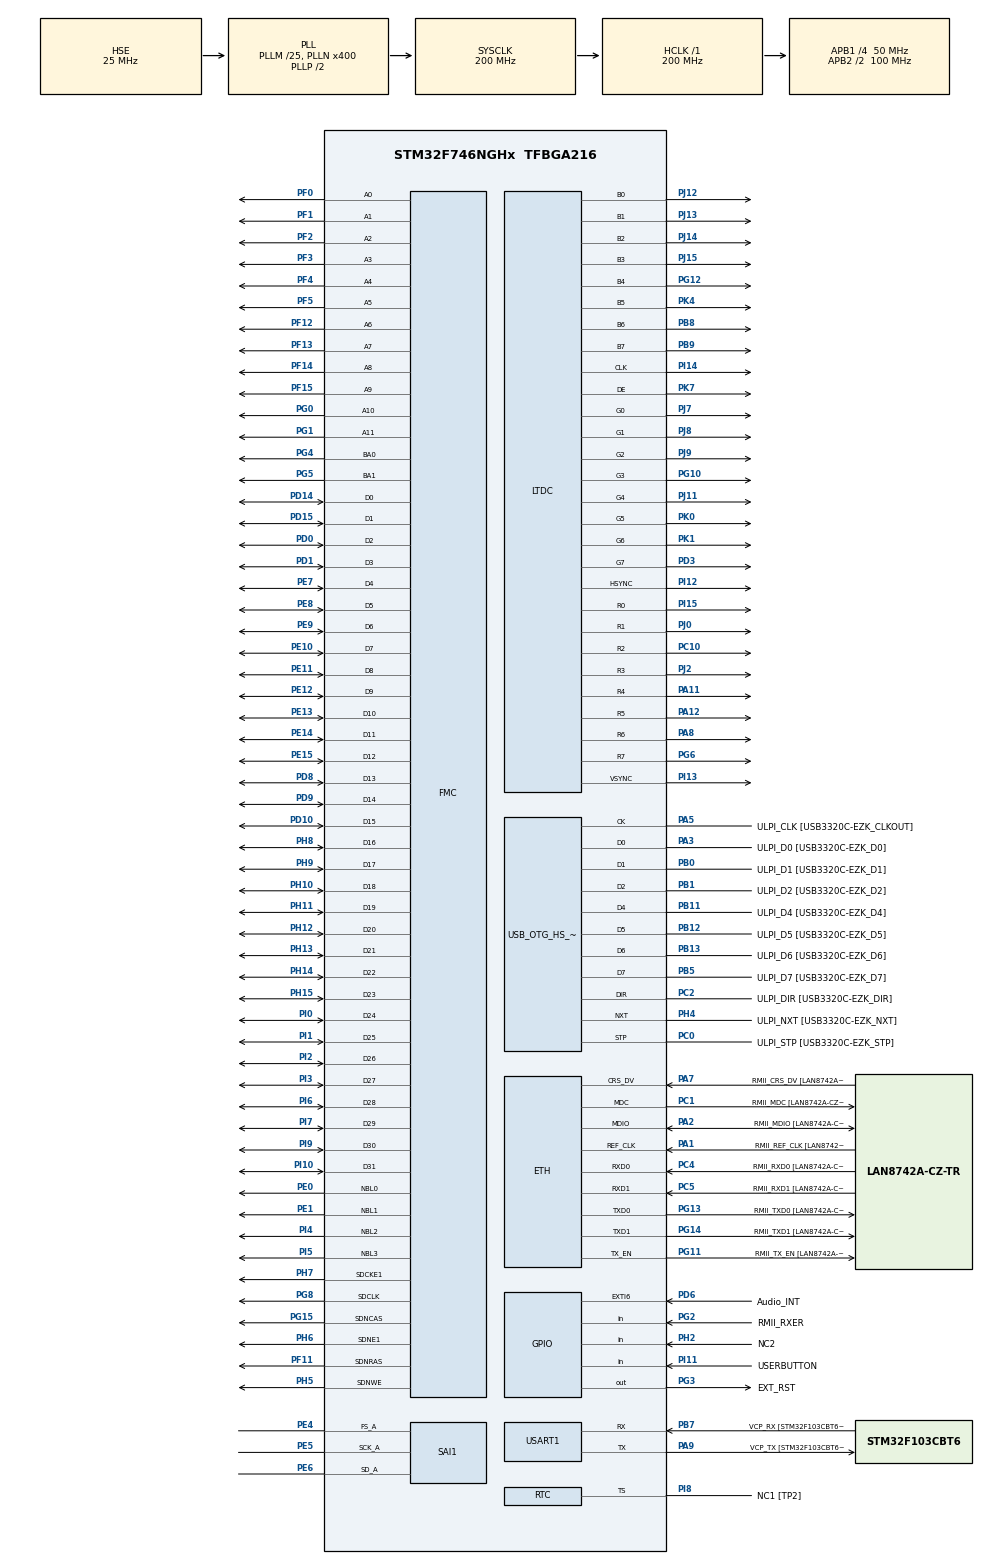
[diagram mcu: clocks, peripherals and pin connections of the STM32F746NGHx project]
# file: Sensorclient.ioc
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CORTEX_M7.CPU_DCache=Enabled
CORTEX_M7.CPU_ICache=Enabled
CORTEX_M7.PREFETCH_ENABLE=1
CORTEX_M7.default_mode_Activation=0
ETH.MACAddr=00\:80\:E1\:00\:00\:01
ETH.MediaInterface=HAL_ETH_RMII_MODE
ETH.PHY_Name=LAN8742A_PHY_ADDRESS
ETH.PHY_RESET_DELAY=0x00000FFF
ETH.PhyAddress=0
FMC.CASLatency1=FMC_SDRAM_CAS_LATENCY_3
FMC.ExitSelfRefreshDelay1=6
FMC.LoadToActiveDelay1=2
FMC.RCDDelay1=2
FMC.RPDelay1=2
FMC.RPDelay2=2
FMC.RowCycleDelay1=6
FMC.RowCycleDelay2=6
FMC.SDClockPeriod1=FMC_SDRAM_CLOCK_PERIOD_2
FMC.SDClockPeriod2=FMC_SDRAM_CLOCK_PERIOD_2
FMC.SelfRefreshTime1=4
FMC.WriteRecoveryTime1=2
LWIP.BSP.number=1
LWIP.LWIP_DBG_TYPES_ON=LWIP_DBG_ON
LWIP.LWIP_TCP=1
LWIP.MEMP_NUM_TCP_PCB=1
LWIP.MEMP_NUM_UDP_PCB=1
LWIP.Version=v2.1.2_Cube
LWIP0.BSP.STBoard=false
LWIP0.BSP.api=BSP_COMPONENT_DRIVER
LWIP0.BSP.component=LAN8742
LWIP0.BSP.instance=LAN8742
LWIP0.BSP.name=Driver_PHY
LWIP0.BSP.semaphore=S_LAN8742
LWIP0.BSP.solution=LAN8742
Mcu.Family=STM32F7
Mcu.Name=STM32F746NGHx
Mcu.Package=TFBGA216
NVIC.DMA2D_IRQn=true\:0\:0\:false\:false\:true\:true\:true\:true
NVIC.LTDC_ER_IRQn=true\:0\:0\:false\:false\:true\:true\:true\:true
NVIC.LTDC_IRQn=true\:0\:0\:false\:false\:true\:true\:true\:true
NVIC.PriorityGroup=NVIC_PRIORITYGROUP_4
NVIC.SAI1_IRQn=true\:0\:0\:false\:false\:true\:true\:true\:true
NVIC.TIM6_DAC_IRQn=true\:15\:0\:false\:false\:true\:false\:true\:true
NVIC.TimeBase=TIM6_DAC_IRQn
NVIC.TimeBaseIP=TIM6
PA1.GPIO_Label=RMII_REF_CLK [LAN8742A-CZ-TR_REFCLK0]
PA1.Mode=RMII
PA1.Signal=ETH_REF_CLK
PA11.Mode=RGB888
PA11.Signal=LTDC_R4
PA12.Mode=RGB888
PA12.Signal=LTDC_R5
PA13.GPIO_Label=SWDIO
PA13.Mode=Serial_Wire
PA13.Signal=SYS_JTMS-SWDIO
PA14.GPIO_Label=SWCLK
PA14.Mode=Serial_Wire
PA14.Signal=SYS_JTCK-SWCLK
PA2.GPIO_Label=RMII_MDIO [LAN8742A-CZ-TR_MDIO]
PA2.Mode=RMII
PA2.Signal=ETH_MDIO
PA3.GPIO_Label=ULPI_D0 [USB3320C-EZK_D0]
PA3.Mode=Host_HS
PA3.Signal=USB_OTG_HS_ULPI_D0
PA5.GPIO_Label=ULPI_CLK [USB3320C-EZK_CLKOUT]
PA5.Mode=Host_HS
PA5.Signal=USB_OTG_HS_ULPI_CK
PA7.GPIO_Label=RMII_CRS_DV [LAN8742A-CZ-TR_CRS_DV]
PA7.Mode=RMII
PA7.Signal=ETH_CRS_DV
PA8.Mode=RGB888
PA8.Signal=LTDC_R6
PA9.GPIO_Label=VCP_TX [STM32F103CBT6_PA3]
PA9.GPIO_Mode=GPIO_MODE_AF_PP
PA9.GPIO_PuPd=GPIO_NOPULL
PA9.GPIO_Speed=GPIO_SPEED_FREQ_LOW
PA9.Mode=Asynchronous
PA9.Signal=USART1_TX
PB0.GPIO_Label=ULPI_D1 [USB3320C-EZK_D1]
PB0.Mode=Host_HS
PB0.Signal=USB_OTG_HS_ULPI_D1
PB1.GPIO_Label=ULPI_D2 [USB3320C-EZK_D2]
PB1.Mode=Host_HS
PB1.Signal=USB_OTG_HS_ULPI_D2
PB11.GPIO_Label=ULPI_D4 [USB3320C-EZK_D4]
PB11.Mode=Host_HS
PB11.Signal=USB_OTG_HS_ULPI_D4
PB12.GPIO_Label=ULPI_D5 [USB3320C-EZK_D5]
PB12.Mode=Host_HS
PB12.Signal=USB_OTG_HS_ULPI_D5
PB13.GPIO_Label=ULPI_D6 [USB3320C-EZK_D6]
PB13.Mode=Host_HS
PB13.Signal=USB_OTG_HS_ULPI_D6
PB2.Signal=QUADSPI_CLK
PB5.GPIO_Label=ULPI_D7 [USB3320C-EZK_D7]
PB5.Mode=Host_HS
PB5.Signal=USB_OTG_HS_ULPI_D7
PB6.GPIO_Label=QSPI_NCS [N25Q128A13EF840E_S]
PB6.Signal=QUADSPI_BK1_NCS
PB7.GPIO_Label=VCP_RX [STM32F103CBT6_PA2]
PB7.GPIO_Mode=GPIO_MODE_AF_PP
PB7.GPIO_PuPd=GPIO_NOPULL
PB7.GPIO_Speed=GPIO_SPEED_FREQ_LOW
PB7.Mode=Asynchronous
PB7.Signal=USART1_RX
PB8.Mode=RGB888
PB8.Signal=LTDC_B6
PB9.Mode=RGB888
PB9.Signal=LTDC_B7
PC0.GPIO_Label=ULPI_STP [USB3320C-EZK_STP]
PC0.Mode=Host_HS
PC0.Signal=USB_OTG_HS_ULPI_STP
PC1.GPIO_Label=RMII_MDC [LAN8742A-CZ-TR_MDC]
PC1.Mode=RMII
PC1.Signal=ETH_MDC
PC10.Mode=RGB888
PC10.Signal=LTDC_R2
PC14/OSC32_IN.GPIO_Label=RCC_OSC32_IN
PC14/OSC32_IN.Mode=LSE-External-Oscillator
PC14/OSC32_IN.Signal=RCC_OSC32_IN
PC15/OSC32_OUT.GPIO_Label=RCC_OSC32_OUT
PC15/OSC32_OUT.Mode=LSE-External-Oscillator
PC15/OSC32_OUT.Signal=RCC_OSC32_OUT
PC2.GPIO_Label=ULPI_DIR [USB3320C-EZK_DIR]
PC2.Mode=Host_HS
PC2.Signal=USB_OTG_HS_ULPI_DIR
PC3.GPIO_Label=FMC_SDCKE0 [MT48LC4M32B2B5-6A_CKE]
PC3.Signal=FMC_SDCKE0
PC4.GPIO_Label=RMII_RXD0 [LAN8742A-CZ-TR_RXD0]
PC4.Mode=RMII
PC4.Signal=ETH_RXD0
PC5.GPIO_Label=RMII_RXD1 [LAN8742A-CZ-TR_RXD1]
PC5.Mode=RMII
PC5.Signal=ETH_RXD1
PD0.Signal=FMC_D2_DA2
PD1.Signal=FMC_D3_DA3
PD10.GPIO_Mode=GPIO_MODE_AF_PP
PD10.GPIO_PuPd=GPIO_NOPULL
PD10.GPIO_Speed_High_Default=GPIO_SPEED_FREQ_VERY_HIGH
PD10.Signal=FMC_D15_DA15
PD11.GPIO_Label=QSPI_D0 [N25Q128A13EF840E_DQ0]
PD11.Signal=QUADSPI_BK1_IO0
PD12.GPIO_Label=QSPI_D1 [N25Q128A13EF840E_DQ1]
PD12.Signal=QUADSPI_BK1_IO1
PD13.GPIO_Label=QSPI_D3 [N25Q128A13EF840E_DQ3]
PD13.Signal=QUADSPI_BK1_IO3
PD14.GPIO_Mode=GPIO_MODE_AF_PP
PD14.GPIO_PuPd=GPIO_NOPULL
PD14.GPIO_Speed_High_Default=GPIO_SPEED_FREQ_VERY_HIGH
PD14.Signal=FMC_D0_DA0
PD15.GPIO_Mode=GPIO_MODE_AF_PP
PD15.GPIO_PuPd=GPIO_NOPULL
PD15.GPIO_Speed_High_Default=GPIO_SPEED_FREQ_VERY_HIGH
PD15.Signal=FMC_D1_DA1
PD3.Mode=RGB888
PD3.Signal=LTDC_G7
PD6.GPIO_Label=Audio_INT
PD6.GPIO_ModeDefaultEXTI=GPIO_MODE_EVT_RISING
PD6.Signal=GPXTI6
PD8.GPIO_Mode=GPIO_MODE_AF_PP
PD8.GPIO_PuPd=GPIO_NOPULL
PD8.GPIO_Speed_High_Default=GPIO_SPEED_FREQ_VERY_HIGH
PD8.Signal=FMC_D13_DA13
PD9.GPIO_Mode=GPIO_MODE_AF_PP
PD9.GPIO_PuPd=GPIO_NOPULL
PD9.GPIO_Speed_High_Default=GPIO_SPEED_FREQ_VERY_HIGH
PD9.Signal=FMC_D14_DA14
PE0.GPIO_Mode=GPIO_MODE_AF_PP
PE0.GPIO_PuPd=GPIO_NOPULL
PE0.GPIO_Speed_High_Default=GPIO_SPEED_FREQ_VERY_HIGH
PE0.Signal=FMC_NBL0
PE1.GPIO_Mode=GPIO_MODE_AF_PP
PE1.GPIO_PuPd=GPIO_NOPULL
PE1.GPIO_Speed_High_Default=GPIO_SPEED_FREQ_VERY_HIGH
PE1.Signal=FMC_NBL1
PE10.GPIO_Mode=GPIO_MODE_AF_PP
PE10.GPIO_PuPd=GPIO_NOPULL
PE10.GPIO_Speed_High_Default=GPIO_SPEED_FREQ_VERY_HIGH
PE10.Signal=FMC_D7_DA7
PE11.GPIO_Mode=GPIO_MODE_AF_PP
PE11.GPIO_PuPd=GPIO_NOPULL
PE11.GPIO_Speed_High_Default=GPIO_SPEED_FREQ_VERY_HIGH
PE11.Signal=FMC_D8_DA8
PE12.GPIO_Mode=GPIO_MODE_AF_PP
PE12.GPIO_PuPd=GPIO_NOPULL
PE12.GPIO_Speed_High_Default=GPIO_SPEED_FREQ_VERY_HIGH
PE12.Signal=FMC_D9_DA9
PE13.GPIO_Mode=GPIO_MODE_AF_PP
PE13.GPIO_PuPd=GPIO_NOPULL
PE13.GPIO_Speed_High_Default=GPIO_SPEED_FREQ_VERY_HIGH
PE13.Signal=FMC_D10_DA10
PE14.GPIO_Mode=GPIO_MODE_AF_PP
PE14.GPIO_PuPd=GPIO_NOPULL
PE14.GPIO_Speed_High_Default=GPIO_SPEED_FREQ_VERY_HIGH
PE14.Signal=FMC_D11_DA11
PE15.GPIO_Mode=GPIO_MODE_AF_PP
PE15.GPIO_PuPd=GPIO_NOPULL
PE15.GPIO_Speed_High_Default=GPIO_SPEED_FREQ_VERY_HIGH
PE15.Signal=FMC_D12_DA12
PE2.GPIO_Label=QSPI_D2 [N25Q128A13EF840E_DQ2]
PE2.Signal=QUADSPI_BK1_IO2
PE4.Mode=SAI_A_Master
PE4.Signal=SAI1_FS_A
PE5.Mode=SAI_A_Master
PE5.Signal=SAI1_SCK_A
PE6.Mode=SAI_A_Master
PE6.Signal=SAI1_SD_A
PE7.GPIO_Mode=GPIO_MODE_AF_PP
PE7.GPIO_PuPd=GPIO_NOPULL
PE7.GPIO_Speed_High_Default=GPIO_SPEED_FREQ_VERY_HIGH
PE7.Signal=FMC_D4_DA4
PE8.GPIO_Mode=GPIO_MODE_AF_PP
PE8.GPIO_PuPd=GPIO_NOPULL
PE8.GPIO_Speed_High_Default=GPIO_SPEED_FREQ_VERY_HIGH
PE8.Signal=FMC_D5_DA5
PE9.GPIO_Mode=GPIO_MODE_AF_PP
PE9.GPIO_PuPd=GPIO_NOPULL
PE9.GPIO_Speed_High_Default=GPIO_SPEED_FREQ_VERY_HIGH
PE9.Signal=FMC_D6_DA6
PF0.GPIO_Mode=GPIO_MODE_AF_PP
PF0.GPIO_PuPd=GPIO_NOPULL
PF0.GPIO_Speed_High_Default=GPIO_SPEED_FREQ_VERY_HIGH
PF0.Signal=FMC_A0
PF1.GPIO_Mode=GPIO_MODE_AF_PP
PF1.GPIO_PuPd=GPIO_NOPULL
PF1.GPIO_Speed_High_Default=GPIO_SPEED_FREQ_VERY_HIGH
PF1.Signal=FMC_A1
PF11.GPIO_Mode=GPIO_MODE_AF_PP
PF11.GPIO_PuPd=GPIO_NOPULL
PF11.GPIO_Speed_High_Default=GPIO_SPEED_FREQ_VERY_HIGH
PF11.Signal=FMC_SDNRAS
PF12.GPIO_Mode=GPIO_MODE_AF_PP
PF12.GPIO_PuPd=GPIO_NOPULL
PF12.GPIO_Speed_High_Default=GPIO_SPEED_FREQ_VERY_HIGH
PF12.Signal=FMC_A6
PF13.GPIO_Mode=GPIO_MODE_AF_PP
PF13.GPIO_PuPd=GPIO_NOPULL
PF13.GPIO_Speed_High_Default=GPIO_SPEED_FREQ_VERY_HIGH
PF13.Signal=FMC_A7
PF14.GPIO_Mode=GPIO_MODE_AF_PP
PF14.GPIO_PuPd=GPIO_NOPULL
PF14.GPIO_Speed_High_Default=GPIO_SPEED_FREQ_VERY_HIGH
PF14.Signal=FMC_A8
PF15.GPIO_Mode=GPIO_MODE_AF_PP
PF15.GPIO_PuPd=GPIO_NOPULL
PF15.GPIO_Speed_High_Default=GPIO_SPEED_FREQ_VERY_HIGH
PF15.Signal=FMC_A9
PF2.GPIO_Mode=GPIO_MODE_AF_PP
PF2.GPIO_PuPd=GPIO_NOPULL
PF2.GPIO_Speed_High_Default=GPIO_SPEED_FREQ_VERY_HIGH
PF2.Signal=FMC_A2
PF3.GPIO_Mode=GPIO_MODE_AF_PP
PF3.GPIO_PuPd=GPIO_NOPULL
PF3.GPIO_Speed_High_Default=GPIO_SPEED_FREQ_VERY_HIGH
PF3.Signal=FMC_A3
PF4.GPIO_Mode=GPIO_MODE_AF_PP
PF4.GPIO_PuPd=GPIO_NOPULL
PF4.GPIO_Speed_High_Default=GPIO_SPEED_FREQ_VERY_HIGH
PF4.Signal=FMC_A4
PF5.GPIO_Mode=GPIO_MODE_AF_PP
PF5.GPIO_PuPd=GPIO_NOPULL
PF5.GPIO_Speed_High_Default=GPIO_SPEED_FREQ_VERY_HIGH
PF5.Signal=FMC_A5
PG0.GPIO_Mode=GPIO_MODE_AF_PP
PG0.GPIO_PuPd=GPIO_NOPULL
PG0.GPIO_Speed_High_Default=GPIO_SPEED_FREQ_VERY_HIGH
PG0.Signal=FMC_A10
PG1.GPIO_Mode=GPIO_MODE_AF_PP
PG1.GPIO_PuPd=GPIO_NOPULL
PG1.GPIO_Speed_High_Default=GPIO_SPEED_FREQ_VERY_HIGH
PG1.Signal=FMC_A11
PG10.Mode=RGB888
PG10.Signal=LTDC_G3
PG11.GPIO_Label=RMII_TX_EN [LAN8742A-CZ-TR_TXEN]
PG11.Mode=RMII
PG11.Signal=ETH_TX_EN
PG12.Mode=RGB888
PG12.Signal=LTDC_B4
PG13.GPIO_Label=RMII_TXD0 [LAN8742A-CZ-TR_TXD0]
PG13.Mode=RMII
PG13.Signal=ETH_TXD0
PG14.GPIO_Label=RMII_TXD1 [LAN8742A-CZ-TR_TXD1]
PG14.Mode=RMII
PG14.Signal=ETH_TXD1
PG15.GPIO_Mode=GPIO_MODE_AF_PP
PG15.GPIO_PuPd=GPIO_NOPULL
PG15.GPIO_Speed_High_Default=GPIO_SPEED_FREQ_VERY_HIGH
PG15.Signal=FMC_SDNCAS
PG2.GPIO_Label=RMII_RXER
PG2.Signal=GPIO_Input
PG3.GPIO_Label=EXT_RST
PG3.Signal=GPIO_Output
PG4.GPIO_Mode=GPIO_MODE_AF_PP
PG4.GPIO_PuPd=GPIO_NOPULL
PG4.GPIO_Speed_High_Default=GPIO_SPEED_FREQ_VERY_HIGH
PG4.Signal=FMC_A14_BA0
PG5.GPIO_Mode=GPIO_MODE_AF_PP
PG5.GPIO_PuPd=GPIO_NOPULL
PG5.GPIO_Speed_High_Default=GPIO_SPEED_FREQ_VERY_HIGH
PG5.Signal=FMC_A15_BA1
PG6.Mode=RGB888
PG6.Signal=LTDC_R7
PG8.GPIO_Mode=GPIO_MODE_AF_PP
PG8.GPIO_PuPd=GPIO_NOPULL
PG8.GPIO_Speed_High_Default=GPIO_SPEED_FREQ_VERY_HIGH
PG8.Signal=FMC_SDCLK
PH0/OSC_IN.GPIO_Label=OSC_25M [NZ2520SB-25.00M_OUT]
PH0/OSC_IN.Mode=HSE-External-Oscillator
PH0/OSC_IN.Signal=RCC_OSC_IN
PH1/OSC_OUT.Mode=HSE-External-Oscillator
PH1/OSC_OUT.Signal=RCC_OSC_OUT
PH10.Signal=FMC_D18
PH11.Signal=FMC_D19
PH12.Signal=FMC_D20
PH13.Signal=FMC_D21
PH14.Signal=FMC_D22
PH15.Signal=FMC_D23
PH2.GPIO_Label=NC2
PH2.Signal=GPIO_Input
PH3.GPIO_Label=FMC_SDNE0 [MT48LC4M32B2B5-6A_CS]
PH3.Signal=FMC_SDNE0
PH4.GPIO_Label=ULPI_NXT [USB3320C-EZK_NXT]
PH4.Mode=Host_HS
PH4.Signal=USB_OTG_HS_ULPI_NXT
PH5.GPIO_Mode=GPIO_MODE_AF_PP
PH5.GPIO_PuPd=GPIO_NOPULL
PH5.GPIO_Speed_High_Default=GPIO_SPEED_FREQ_VERY_HIGH
PH5.Signal=FMC_SDNWE
PH6.Mode=SdramChipSelect2_1
PH6.Signal=FMC_SDNE1
PH7.Mode=SdramChipSelect2_1
PH7.Signal=FMC_SDCKE1
PH8.Signal=FMC_D16
PH9.Signal=FMC_D17
PI0.Signal=FMC_D24
PI1.Signal=FMC_D25
PI10.Signal=FMC_D31
PI11.GPIO_Label=USERBUTTON
PI11.GPIO_PuPd=GPIO_NOPULL
PI11.Signal=GPIO_Input
PI12.Mode=RGB888
PI12.Signal=LTDC_HSYNC
PI13.Mode=RGB888
PI13.Signal=LTDC_VSYNC
PI14.Mode=RGB888
PI14.Signal=LTDC_CLK
PI15.Mode=RGB888
PI15.Signal=LTDC_R0
PI2.Signal=FMC_D26
PI3.Signal=FMC_D27
PI4.Signal=FMC_NBL2
PI5.Signal=FMC_NBL3
PI6.Signal=FMC_D28
PI7.Signal=FMC_D29
PI8.GPIO_Label=NC1 [TP2]
PI8.Mode=Timestamp enabled - Input Enabled to TS
PI8.Signal=RTC_TS
PI9.Signal=FMC_D30
PJ0.Mode=RGB888
PJ0.Signal=LTDC_R1
PJ11.Mode=RGB888
PJ11.Signal=LTDC_G4
PJ12.Mode=RGB888
PJ12.Signal=LTDC_B0
PJ13.Mode=RGB888
PJ13.Signal=LTDC_B1
PJ14.Mode=RGB888
PJ14.Signal=LTDC_B2
PJ15.Mode=RGB888
PJ15.Signal=LTDC_B3
PJ2.Mode=RGB888
PJ2.Signal=LTDC_R3
PJ7.Mode=RGB888
PJ7.Signal=LTDC_G0
PJ8.Mode=RGB888
PJ8.Signal=LTDC_G1
PJ9.Mode=RGB888
PJ9.Signal=LTDC_G2
PK0.Mode=RGB888
PK0.Signal=LTDC_G5
PK1.Mode=RGB888
PK1.Signal=LTDC_G6
PK4.Mode=RGB888
PK4.Signal=LTDC_B5
PK7.Mode=RGB888
PK7.Signal=LTDC_DE
ProjectManager.HeapSize=0x200
ProjectManager.StackSize=0x400
ProjectManager.TargetToolchain=STM32CubeIDE
RCC.AHBFreq_Value=200000000
RCC.APB1CLKDivider=RCC_HCLK_DIV4
RCC.APB1Freq_Value=50000000
RCC.APB1TimFreq_Value=100000000
RCC.APB2CLKDivider=RCC_HCLK_DIV2
RCC.APB2Freq_Value=100000000
RCC.APB2TimFreq_Value=200000000
RCC.CortexFreq_Value=200000000
RCC.HCLKFreq_Value=200000000
RCC.HSE_VALUE=25000000
RCC.HSI_VALUE=16000000
RCC.PLL48CLockSelection=RCC_CLK48SOURCE_PLLSAIP
RCC.PLLI2SN=100
RCC.PLLM=25
RCC.PLLN=400
RCC.PLLQ=9
RCC.PLLSAIN=384
RCC.PLLSAIP=RCC_PLLSAIP_DIV8
RCC.PLLSAIR=5
RCC.PLLSAIRDiv=RCC_PLLSAIDIVR_8
RCC.PLLSourceVirtual=RCC_PLLSOURCE_HSE
RCC.SDMMCClockSelection=RCC_SDMMC1CLKSOURCE_CLK48
RCC.SYSCLKFreq_VALUE=200000000
RCC.SYSCLKSource=RCC_SYSCLKSOURCE_PLLCLK
RCC.USBFreq_Value=48000000
RCC.VCOOutputFreq_Value=400000000
SAI1.AudioFrequency-SAI_A_Master=SAI_AUDIO_FREQUENCY_192K
SAI1.AudioMode-SAI_A_Master=SAI_MODEMASTER_RX
SAI1.BasicDataSize-SAI_A_Master=SAI_PROTOCOL_DATASIZE_32BIT
SAI1.BasicProtocol-SAI_A_Master=SAI_PCM_LONG
SAI1.ErrorAudioFreq-SAI_A_Master=-2.34 %
SAI1.InitProtocol-SAI_A_Master=Enable
SAI1.Instance-SAI_A_Master=SAI$Index_Block_A
SAI1.MClockEnable-SAI_A_Master=SAI_MASTERCLOCK_DISABLE
SAI1.OutputDrive-SAI_A_Master=SAI_OUTPUTDRIVE_ENABLE
SAI1.RealAudioFreq-SAI_A_Master=187.5 KHz
SAI1.VirtualMode-SAI_A_Master=VM_MASTER
SAI1.VirtualProtocol-SAI_A_BASIC=VM_BASIC_PROTOCOL
SH.FMC_A0.0=FMC_A0,12b-sda1
SH.FMC_A1.0=FMC_A1,12b-sda1
SH.FMC_A10.0=FMC_A10,12b-sda1
SH.FMC_A11.0=FMC_A11,12b-sda1
SH.FMC_A14_BA0.0=FMC_BA0,FourSdramBanks1
SH.FMC_A15_BA1.0=FMC_BA1,FourSdramBanks1
SH.FMC_A2.0=FMC_A2,12b-sda1
SH.FMC_A3.0=FMC_A3,12b-sda1
SH.FMC_A4.0=FMC_A4,12b-sda1
SH.FMC_A5.0=FMC_A5,12b-sda1
SH.FMC_A6.0=FMC_A6,12b-sda1
SH.FMC_A7.0=FMC_A7,12b-sda1
SH.FMC_A8.0=FMC_A8,12b-sda1
SH.FMC_A9.0=FMC_A9,12b-sda1
SH.FMC_D0_DA0.0=FMC_D0,sd-32b-d1
SH.FMC_D10_DA10.0=FMC_D10,sd-32b-d1
SH.FMC_D11_DA11.0=FMC_D11,sd-32b-d1
SH.FMC_D12_DA12.0=FMC_D12,sd-32b-d1
SH.FMC_D13_DA13.0=FMC_D13,sd-32b-d1
SH.FMC_D14_DA14.0=FMC_D14,sd-32b-d1
SH.FMC_D15_DA15.0=FMC_D15,sd-32b-d1
SH.FMC_D16.0=FMC_D16,sd-32b-d1
SH.FMC_D17.0=FMC_D17,sd-32b-d1
SH.FMC_D18.0=FMC_D18,sd-32b-d1
SH.FMC_D19.0=FMC_D19,sd-32b-d1
SH.FMC_D1_DA1.0=FMC_D1,sd-32b-d1
SH.FMC_D20.0=FMC_D20,sd-32b-d1
SH.FMC_D21.0=FMC_D21,sd-32b-d1
SH.FMC_D22.0=FMC_D22,sd-32b-d1
SH.FMC_D23.0=FMC_D23,sd-32b-d1
SH.FMC_D24.0=FMC_D24,sd-32b-d1
SH.FMC_D25.0=FMC_D25,sd-32b-d1
SH.FMC_D26.0=FMC_D26,sd-32b-d1
SH.FMC_D27.0=FMC_D27,sd-32b-d1
SH.FMC_D28.0=FMC_D28,sd-32b-d1
SH.FMC_D29.0=FMC_D29,sd-32b-d1
SH.FMC_D2_DA2.0=FMC_D2,sd-32b-d1
SH.FMC_D30.0=FMC_D30,sd-32b-d1
SH.FMC_D31.0=FMC_D31,sd-32b-d1
SH.FMC_D3_DA3.0=FMC_D3,sd-32b-d1
SH.FMC_D4_DA4.0=FMC_D4,sd-32b-d1
SH.FMC_D5_DA5.0=FMC_D5,sd-32b-d1
SH.FMC_D6_DA6.0=FMC_D6,sd-32b-d1
SH.FMC_D7_DA7.0=FMC_D7,sd-32b-d1
SH.FMC_D8_DA8.0=FMC_D8,sd-32b-d1
SH.FMC_D9_DA9.0=FMC_D9,sd-32b-d1
SH.FMC_NBL0.0=FMC_NBL0,Sd4ByteEnable1
SH.FMC_NBL1.0=FMC_NBL1,Sd4ByteEnable1
SH.FMC_NBL2.0=FMC_NBL2,Sd4ByteEnable1
SH.FMC_NBL3.0=FMC_NBL3,Sd4ByteEnable1
SH.FMC_SDCLK.0=FMC_SDCLK,12b-sda1
SH.FMC_SDNCAS.0=FMC_SDNCAS,12b-sda1
SH.FMC_SDNRAS.0=FMC_SDNRAS,12b-sda1
SH.FMC_SDNWE.0=FMC_SDNWE,12b-sda1
USART1.VirtualMode-Asynchronous=VM_ASYNC
VP_CRC_VS_CRC.Mode=CRC_Activate
VP_DMA2D_VS_DMA2D.Mode=DMA2D_Activate
VP_LWIP_VS_Enabled.Mode=Enabled
VP_PDM2PCM_VS_PDM2PCM.Mode=PDM2PCM_Channel
VP_RNG_VS_RNG.Mode=RNG_Activate
VP_RTC_VS_RTC_Activate.Mode=RTC_Enabled
VP_RTC_VS_RTC_Calendar.Mode=RTC_Calendar
VP_SAI1_VP_$IpInstance_SAIA_SAI_BASIC.Mode=SAI_A_BASIC
VP_SYS_VS_tim6.Mode=TIM6
VP_TIM1_VS_ClockSourceINT.Mode=Internal
board=STM32F746G-DISCO

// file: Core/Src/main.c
/* USER CODE BEGIN Header */
/**
  ******************************************************************************
  * @file           : main.c
  * @brief          : Main program body
  ******************************************************************************
  * @attention
  *
  * Copyright (c) 2022 STMicroelectronics.
  * All rights reserved.
  *
  * This software is licensed under terms that can be found in the LICENSE file
  * in the root directory of this software component.
  * If no LICENSE file comes with this software, it is provided AS-IS.
  *
  ******************************************************************************
  */
/* USER CODE END Header */
#include "main.h"
#include "crc.h"
#include "dma2d.h"
#include "ltdc.h"
#include "lwip.h"
#include "pdm2pcm.h"
#include "rng.h"
#include "rtc.h"
#include "sai.h"
#include "tim.h"
#include "usart.h"
#include "gpio.h"
#include "fmc.h"

/* USER CODE BEGIN Includes */
#include "stm32746g_discovery.h"  // get LED and BUTTONS stuff
#include "stm32746g_discovery_sdram.h"
#include "helperfunctions.h"
/* USER CODE END Includes */

/* USER CODE BEGIN PD */
#define SDRAM __attribute__((section(".SDRAM_EX")))
/* USER CODE END PD */

/* USER CODE BEGIN PV */
  uint32_t SDRAM extern_array[0x800000/4];   // range[0 - 2097151]
/* USER CODE END PV */

void SystemClock_Config(void);
void PeriphCommonClock_Config(void);

int main(void)
{

  /* Enable I-Cache---------------------------------------------------------*/
  SCB_EnableICache();

  /* Enable D-Cache---------------------------------------------------------*/
  SCB_EnableDCache();

  /* MCU Configuration--------------------------------------------------------*/

  /* Reset of all peripherals, Initializes the Flash interface and the Systick. */
  HAL_Init();

  /* Configure the system clock */
  SystemClock_Config();

/* Configure the peripherals common clocks */
  PeriphCommonClock_Config();

  /* Initialize all configured peripherals */
  MX_GPIO_Init();
  MX_CRC_Init();
  MX_FMC_Init();
  MX_RTC_Init();
  MX_TIM1_Init();
  MX_USART1_UART_Init();
  MX_RNG_Init();
  MX_LWIP_Init();
  MX_PDM2PCM_Init();
  MX_SAI1_Init();
  MX_DMA2D_Init();
  MX_LTDC_Init();
  /* USER CODE BEGIN 2 */
  // Start SDRAM Config
	if (BSP_SDRAM_Init() != SDRAM_OK)
	{
		Error_Handler();
	}
  /**
   * array to test SDram
   * BSP_SDRAM_WriteData_DMA();
   * BSP_SDRAM_ReadData_DMA();
   * from driver .h file: DMA_CHANNEL_0, DMA2_Stream0
   *
   */

	volatile uint32_t SDRAM_datapointer = 0;
	volatile uint32_t SDRAM_dummydata = 0;
	volatile uint32_t targetarray = 0;
	//linker script definition
	//https://stackoverflow.com/questions/48561217/how-to-get-value-of-variable-defined-in-ld-linker-script-from-c/54728097#54728097
	//https://www.mikrocontroller.net/topic/364403
	//https://github.com/MaJerle/stm32f429/blob/main/14-STM32F429_SDRAM_VARIABLES/User/main.c

	/*	extern uint8_t _sdram_data_begin[];
	extern uint8_t _sdram_data_end[];
	uint32_t start_of_sdram = (uint32_t)_sdram_data_begin;
	uint32_t end_of_sdram = (uint32_t)_sdram_data_end;
	char sdram_buffer[SDRAM_BUFFER_SIZE] __attribute__((section (".sdram_data")));

// SDRAM manual test
	const uint32_t testdatasize = 10;
	//uint32_t sourcearray[testdatasize];
	uint32_t targetarray[testdatasize];

	uint32_t SDRAM_absolute_start = SDRAM_DEVICE_ADDR;
	uint32_t SDRAM_absolute_end = SDRAM_DEVICE_ADDR+SDRAM_DEVICE_SIZE;
	volatile uint32_t SDRAM_datapointer = SDRAM_absolute_start;
	volatile uint32_t SDRAM_dummydata = 0;
	// fill array start

	for(uint32_t i=0; i< SDRAM_absolute_end; i+4)
	{
		SDRAM_datapointer = SDRAM_datapointer + i;  // TODO: bug with SDRAM_datapointer
		SDRAM_dummydata = (SDRAM_dummydata+i) % 0xFFFFFFF;  // modulo for max uint32_t

//		if( BSP_SDRAM_WriteData(SDRAM_datapointer, &SDRAM_dummydata, 1 ) != SDRAM_OK ){
//			  Error_Handler();
//		}

	}
	*/
  /* startadress from driver .h file
   * SDRAM_DEVICE_ADDR  ((uint32_t)0xC0000000)
   * #define SDRAM_DEVICE_SIZE  ((uint32_t)0x800000)  // SDRAM device size in MBytes
   * 64 Mbit = 8 MByte, 0x800000 = 8 * 1024 * 1024
   */

/*
  if( BSP_SDRAM_WriteData(RAM_relative_addr, sourcearray, testdatasize ) != SDRAM_OK ){
	  Error_Handler();

  if(BSP_SDRAM_ReadData(SDRAM_absolute_start-testdatasize, targetarray, testdatasize ) != SDRAM_OK ){
	  Error_Handler();
  }
   }*/
/*  for(int i=0; i<testdatasize; i++){
	  targetarray[i] = sourcearray[i];

  }*/

  //uint32_t newline[5] = {0x41,0x2d,0x42, 0x0d, 0x0a};  // W-G CR LF
//  uint8_t printline[6] = {0xAF,0x00,0x00,0xFE,0x0d,0x0a};

  //size_t printline_size = ARRAY_LENGTH(printline);

  size_t sendonce = 0;
  uint32_t iterator = 0;
  uint8_t printme[4];
/*
  if (HAL_UART_Transmit(&huart1, start_of_sdram, 4, 1000) != HAL_OK)  // sending to Linux /dev/ttyACM0, can only transmit 16 bis max
  {
	  Error_Handler();
  }
*/
  /* USER CODE END 2 */

  /* Infinite loop */
  /* USER CODE BEGIN WHILE */
  while (1)
  {

/*	  //USERBUTTON_Pin
	  if (HAL_UART_Transmit(&huart1, newline, newline_size, 1000) != HAL_OK)  // sending to Linux /dev/ttyACM0
	  {
		  Error_Handler();
	  }
	  HAL_Delay(1000);
	  if (HAL_UART_Transmit(&huart1, testdatasize, 1, 1000) != HAL_OK)  // sending to Linux /dev/ttyACM0
	  {
		  Error_Handler();
	  }
	  HAL_Delay(1000);

*/

	if(HAL_GPIO_ReadPin(USERBUTTON_GPIO_Port, USERBUTTON_Pin))
	{
		for(uint32_t i=0; i< 50; i++)
		{

			SDRAM_datapointer = SDRAM_datapointer + iterator*4;  // TODO: bug with SDRAM_datapointer
			SDRAM_dummydata = iterator+20 ;  // modulo for max uint32_t   % 0xFFFFFFF
			iterator++;

			if( BSP_SDRAM_WriteData(SDRAM_datapointer, &SDRAM_dummydata, 4 ) != SDRAM_OK ){  Error_Handler(); }

			if(BSP_SDRAM_ReadData(SDRAM_datapointer, &targetarray, 4  ) != SDRAM_OK ){  Error_Handler();  }

			printme[0] = (uint8_t)targetarray;
			printme[1] = (uint8_t)targetarray>>8;
			printme[2] = (uint8_t)targetarray>>16;
			printme[3] = (uint8_t)targetarray>>24;

			for(int j=0; j<4; j++)
			{

				if (HAL_UART_Transmit(&huart1, printme[j], 1, 1000) != HAL_OK)  // sending to Linux /dev/ttyACM0
				{
				  Error_Handler();  //TODO error exit here on button press on first try
				}
			}
			HAL_Delay(1000);
		}

	}

    /* USER CODE END WHILE */

  }
}

void SystemClock_Config(void)
{
  RCC_OscInitTypeDef RCC_OscInitStruct = {0};
  RCC_ClkInitTypeDef RCC_ClkInitStruct = {0};

  /** Configure LSE Drive Capability
  */
  HAL_PWR_EnableBkUpAccess();

  /** Configure the main internal regulator output voltage
  */
  __HAL_RCC_PWR_CLK_ENABLE();
  __HAL_PWR_VOLTAGESCALING_CONFIG(PWR_REGULATOR_VOLTAGE_SCALE1);

  /** Initializes the RCC Oscillators according to the specified parameters
  * in the RCC_OscInitTypeDef structure.
  */
  RCC_OscInitStruct.OscillatorType = RCC_OSCILLATORTYPE_LSI|RCC_OSCILLATORTYPE_HSE;
  RCC_OscInitStruct.HSEState = RCC_HSE_ON;
  RCC_OscInitStruct.LSIState = RCC_LSI_ON;
  RCC_OscInitStruct.PLL.PLLState = RCC_PLL_ON;
  RCC_OscInitStruct.PLL.PLLSource = RCC_PLLSOURCE_HSE;
  RCC_OscInitStruct.PLL.PLLM = 25;
  RCC_OscInitStruct.PLL.PLLN = 400;
  RCC_OscInitStruct.PLL.PLLP = RCC_PLLP_DIV2;
  RCC_OscInitStruct.PLL.PLLQ = 9;
  if (HAL_RCC_OscConfig(&RCC_OscInitStruct) != HAL_OK)
  {
    Error_Handler();
  }

  /** Activate the Over-Drive mode
  */
  if (HAL_PWREx_EnableOverDrive() != HAL_OK)
  {
    Error_Handler();
  }

  /** Initializes the CPU, AHB and APB buses clocks
  */
  RCC_ClkInitStruct.ClockType = RCC_CLOCKTYPE_HCLK|RCC_CLOCKTYPE_SYSCLK
                              |RCC_CLOCKTYPE_PCLK1|RCC_CLOCKTYPE_PCLK2;
  RCC_ClkInitStruct.SYSCLKSource = RCC_SYSCLKSOURCE_PLLCLK;
  RCC_ClkInitStruct.AHBCLKDivider = RCC_SYSCLK_DIV1;
  RCC_ClkInitStruct.APB1CLKDivider = RCC_HCLK_DIV4;
  RCC_ClkInitStruct.APB2CLKDivider = RCC_HCLK_DIV2;

  if (HAL_RCC_ClockConfig(&RCC_ClkInitStruct, FLASH_LATENCY_6) != HAL_OK)
  {
    Error_Handler();
  }
}

void PeriphCommonClock_Config(void)
{
  RCC_PeriphCLKInitTypeDef PeriphClkInitStruct = {0};

  /** Initializes the peripherals clock
  */
  PeriphClkInitStruct.PeriphClockSelection = RCC_PERIPHCLK_LTDC|RCC_PERIPHCLK_SAI1
                              |RCC_PERIPHCLK_CLK48;
  PeriphClkInitStruct.PLLSAI.PLLSAIN = 384;
  PeriphClkInitStruct.PLLSAI.PLLSAIR = 5;
  PeriphClkInitStruct.PLLSAI.PLLSAIQ = 2;
  PeriphClkInitStruct.PLLSAI.PLLSAIP = RCC_PLLSAIP_DIV8;
  PeriphClkInitStruct.PLLSAIDivQ = 1;
  PeriphClkInitStruct.PLLSAIDivR = RCC_PLLSAIDIVR_8;
  PeriphClkInitStruct.Sai1ClockSelection = RCC_SAI1CLKSOURCE_PLLSAI;
  PeriphClkInitStruct.Clk48ClockSelection = RCC_CLK48SOURCE_PLLSAIP;
  if (HAL_RCCEx_PeriphCLKConfig(&PeriphClkInitStruct) != HAL_OK)
  {
    Error_Handler();
  }
}

void HAL_TIM_PeriodElapsedCallback(TIM_HandleTypeDef *htim)
{
  if (htim->Instance == TIM6) {
    HAL_IncTick();
  }
}

void Error_Handler(void)
{
  /* USER CODE BEGIN Error_Handler_Debug */
	//TODO: Error assertion
	// https://stackoverflow.com/questions/53123403/how-to-find-which-function-is-calling-another-function-in-c
	#ifdef DEBUG
	  asm("BKPT #0");
	#else
	  while(1) {
		HAL_Delay(250);
		HAL_GPIO_TogglePin(LED1_GPIO_PORT, LED1_PIN);// user LEDs are used by SD-RAM
	  }
	#endif

	// print errorcode line here
  /* User can add his own implementation to report the HAL error return state */
  __disable_irq();
  while (1)
  {
  }
  /* USER CODE END Error_Handler_Debug */
}
